# 3066H register map
File version: 1.0
Registers are 32-bit, access per field, reset 0x0 unless marked. A register's access mark holds for its fields unless they carry their own. Offsets are from the block's base; [hi:lo] are bit positions; {n}, {i} and the like mark numbered series; 'fields as' and 'values as' point back to an identical list.

## APT_XBAR — APT_XBAR peripheral interface
Base 0x14A1F000
0x00 TRIP_XBAR_IN31_0_CFG rw — TRIP_XBAR_IN31_0_CFG为TRIP XBAR INPUT配置寄存器。支持写保护。
  [31:0] rg_xbar_in31_0_inv — 选择TRIP X-BAR INPUT31~INPUT0是否取反，每个bit对应1个INPUT。 0：直通，不取反； 1：取反。
0x04 TRIP_XBAR_IN63_32_CFG rw — TRIP_XBAR_IN63_32_CFG为TRIP XBAR INPUT配置寄存器。支持写保护。
  [31:0] rg_xbar_in63_32_inv — 选择TRIP X-BAR INPUT63~INPUT32是否取反，每个bit对应1个INPUT。 0：直通，不取反； 1：取反。
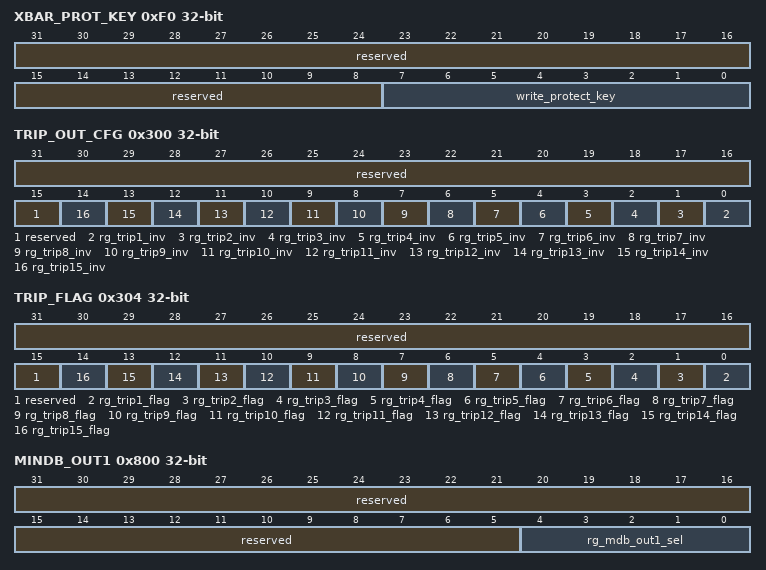
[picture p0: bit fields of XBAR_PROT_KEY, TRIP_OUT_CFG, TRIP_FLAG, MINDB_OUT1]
0xF0 XBAR_PROT_KEY — XBAR_PROT_KEY为XBAR保护配置寄存器。
  [31:8] reserved ro — 保留。
  [7:0] write_protect_key rw — XBAR写保护关键字。 0x55：软件可写支持写保护的寄存器； 其他：软件不可写支持写保护的寄存器，只可读。
{0xF0+0x10*i} TRIP{i}_IN31_0_CFG rw (i=1..15) — TRIP{i}_IN31_0_CFG为TRIP{i} INPUT31_0配置寄存器。支持写保护。
  [31:0] rg_xbar_in31_0_trip{i}_en — 选择TRIP X-BAR INPUT31~INPUT0是否对TRIP{i}使能，每个bit对应1个INPUT。 0：不使能； 1：使能。
{0xF4+0x10*i} TRIP{i}_IN63_32_CFG rw (i=1..15) — TRIP{i}_IN63_32_CFG为TRIP{i} INPUT63_32配置寄存器。支持写保护。
  [31:0] rg_xbar_in63_32_trip{i}_en — 选择TRIP X-BAR INPUT63~INPUT32是否对TRIP{i}使能，每个bit对应1个INPUT。 0：不使能； 1：使能。
0x300 TRIP_OUT_CFG — TRIP_OUT_CFG为TRIP输出配置寄存器。支持写保护。
  [31:15] reserved ro — 保留。
  [n-1] rg_trip{n}_inv rw (n=1..15) — 选择TRIP XBAR输出极性。 0：直通，不取反； 1：取反。
0x304 TRIP_FLAG access not given — TRIP_FLAG为TRIP标志寄存器。支持写保护。
  [31:15] reserved ro — 保留。
  [n-1] rg_trip{n}_flag (n=1..15) — TRIP{n}标志，TRIP{n}是否被触发。 0：TRIP{n}没被触发； 1：TRIP{n}被触发，软件写1清除。 信号上升沿触发置位，置位优先于软件清除。
0x800 MINDB_OUT1 — MINDB_OUT1为MINDB XBAR OUT1配置寄存器。支持写保护。
  [31:5] reserved ro — 保留。
  [4:0] rg_mdb_out1_sel rw — 选择MINDB XBAR OUT1输出来源。 0x0：APT0_DG_PWMA_NO_HR； 0x1：APT0_DG_PWMB_NO_HR； 0x2：APT1_DG_PWMA_NO_HR； 0x3：APT1_DG_PWMB_NO_HR； … 0x1E：APT15_DG_PWMA_NO_HR； 0x1F：APT15_DG_PWMA_NO_HR； 最大值到最后一个APT，其他值保留。
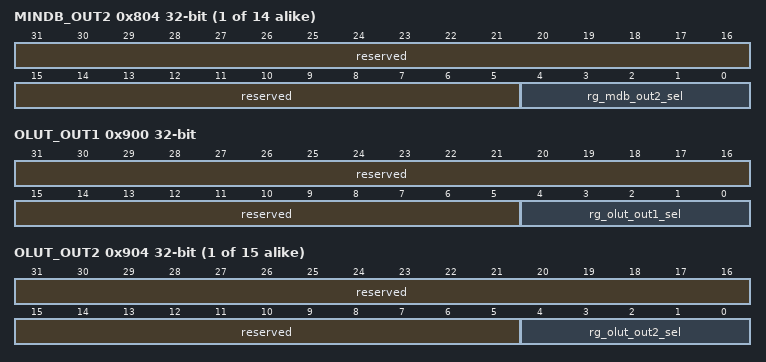
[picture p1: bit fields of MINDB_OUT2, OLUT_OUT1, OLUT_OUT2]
{0x7FC+4i} MINDB_OUT{i} (i=2..15) — MINDB_OUT{i}为MINDB XBAR OUT{i}配置寄存器。支持写保护。
  [31:5] reserved ro — 保留。
  [4:0] rg_mdb_out{i}_sel rw — 选择MINDB XBAR OUT{i}输出来源。
0x900 OLUT_OUT1 — OLUT_OUT1为OLUT XBAR OUT1配置寄存器。支持写保护。
  [31:5] reserved ro — 保留。
  [4:0] rg_olut_out1_sel rw — 选择OLUT XBAR OUT1输出来源。 0x0：APT0_MINDB_PWMA； 0x1：APT0_MINDB_PWMB； 0x2：APT1_MINDB_PWMA； 0x3：APT1_MINDB_PWMB； … 0x1E：APT15_MINDB_PWMA； 0x1F：APT15_MINDB_PWMB； 最大值到最后一个APT，其他值保留。
{0x8FC+4i} OLUT_OUT{i} (i=2..16) — OLUT_OUT{i}为OLUT XBAR OUT{i}配置寄存器。支持写保护。
  [31:5] reserved ro — 保留。
  [4:0] rg_olut_out{i}_sel rw — 选择OLUT XBAR OUT{i}输出来源。

## DLL — DLL peripheral interface
Base 0x14A1FF00
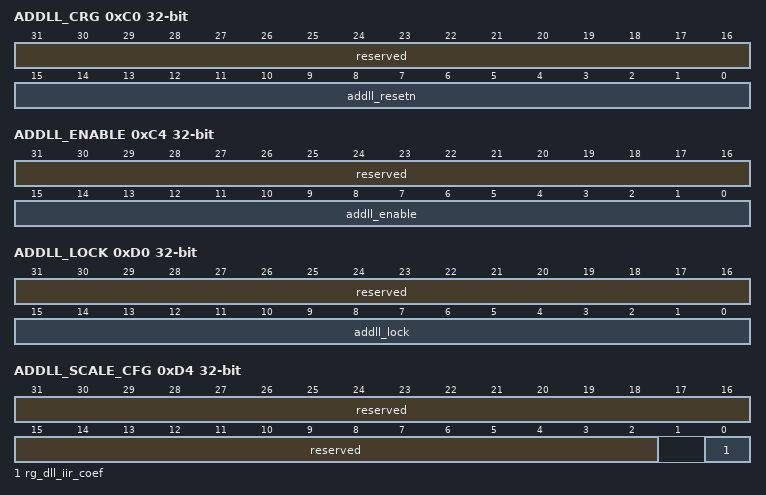
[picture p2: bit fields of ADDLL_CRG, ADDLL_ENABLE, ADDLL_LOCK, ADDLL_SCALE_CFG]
0xC0 ADDLL_CRG — ADDLL复位寄存器
  [31:16] reserved ro — 保留。
  [15:0] addll_resetn rw — ADDLL复位，bit[15]-bit[0]分别对应ADDLL15-ADDLL0复位。 0：复位； 1：不复位。
0xC4 ADDLL_ENABLE — ADDLL使能寄存器
  [31:16] reserved ro — 保留。
  [15:0] addll_enable rw — ADDLL使能，bit[15]-bit[0]分别对应ADDLL15-ADDLL0使能。 0：不使能； 1：使能。
0xC4 ADDLL_ENABLE — ADDLL使能寄存器
  fields as ADDLL_ENABLE
0xD0 ADDLL_LOCK ro — ADDLL锁定状态寄存器
  [31:16] reserved — 保留。
  [15:0] addll_lock — ADDLL锁定状态，bit[15]-bit[0]分别对应ADDLL15-ADDLL0锁定状态。 0：未锁定； 1：已锁定。
0xD4 ADDLL_SCALE_CFG — ADDLL SCLAE配置寄存器
  [31:2] reserved ro — 保留。
  [0] rg_dll_iir_coef rw — 对SCALE进行IIR滤波，滤波系数。 00：K=1/2； 01：K=1/4； 10：K=1/8。 其他：保留。

## CAPM_COMM — CAPM_COMM peripheral interface
Base 0x14B03000
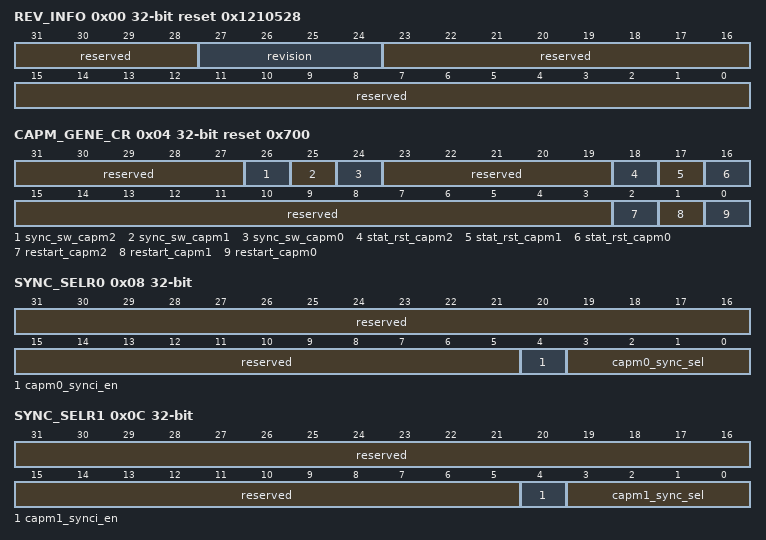
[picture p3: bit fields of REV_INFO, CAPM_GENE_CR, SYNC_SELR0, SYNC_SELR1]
0x00 REV_INFO ro reset 0x1210528 — REV_INFO为Revision Information，版本信息寄存器。
  [31:28] reserved — 保留。
  [27:24] revision — IP版本号。
  [23:0] reserved — 保留。
0x04 CAPM_GENE_CR reset 0x700 — CAPM_GENE_CR为Capture Module General Control Register，通用配置寄存器。
  [31:27] reserved ro — 保留。
  [26] sync_sw_capm2 rw write-1-clears — 触发CAPM2同步，TSR的值被同步为SYNC_PHS的值，同时重启捕获序列。软件写1后自动清零。 0：不同步； 1：同步。写1后自动清零。
  [25] sync_sw_capm1 rw write-1-clears — 触发CAPM1同步，TSR的值被同步为SYNC_PHS的值，同时重启捕获序列。软件写1后自动清零。 0：不同步； 1：同步。写1后自动清零。
  [24] sync_sw_capm0 rw write-1-clears — 触发CAPM0同步，TSR的值被同步为SYNC_PHS的值，同时重启捕获序列。软件写1后自动清零。 0：不同步； 1：同步。写1后自动清零。
  [23:19] reserved ro — 保留。
  [18] stat_rst_capm2 rw write-1-clears — CAPM2工作状态复位，复位范围包括：TSR计数器；EAR计数器；捕获序列；TSR分频计数器；原始中断。 0：不复位； 1：复位。写1后自动清零。
  [17] stat_rst_capm1 rw write-1-clears — CAPM1工作状态复位，复位范围包括：TSR计数器、EAR计数器、捕获序列、TSR分频计数器、原始中断。 0：不复位； 1：复位。写1后自动清零。
  [16] stat_rst_capm0 rw write-1-clears — CAPM0工作状态复位，复位范围包括：TSR计数器、EAR计数器、捕获序列、TSR分频计数器、原始中断。 0：不复位； 1：复位。写1后自动清零。
  [15:3] reserved ro — 保留。
  [2] restart_capm2 rw write-1-clears — CAPM2开始一次新的单轮次捕获。 0：不开始； 1：开始。写1后自动清零。
  [1] restart_capm1 rw write-1-clears — CAPM1开始一次新的单轮次捕获。 0：不开始； 1：开始。写1后自动清零。
  [0] restart_capm0 rw write-1-clears — CAPM0开始一次新的单轮次捕获。 0：不开始； 1：开始。写1后自动清零。
0x08 SYNC_SELR0 — SYNC_SELR0为Sync Selection Register(for CAPM0)，CAPM0同步设置选择寄存器。
  [31:5] reserved ro — 保留。
  [4] capm0_synci_en rw — CAPM0 硬件，软件同步使能。 0：不使能； 1：使能。
  [3:0] capm0_sync_sel rw — CAPM0的硬件同步源选择。 0x0：无同步源； 0x1：APT0同步输出信号APT0SYNCO； 0x2：APT1同步输出信号APT1SYNCO； 0x3：APT2同步输出信号APT2SYNCO； 0x4：APT3同步输出信号APT3SYNCO； 0x5：APT4同步输出信号APT4SYNCO； 0x6：APT5同步输出信号APT5SYNCO； 0x7：APT6同步输出信号APT6SYNCO； 0x8：APT7同步输出信号APT7SYNCO； 0x9：APT8同步输出信号APT8SYNCO； 其他：无同步源。
0x0C SYNC_SELR1 — SYNC_SELR1为Sync Selection Register(for CAPM1)，CAPM1同步设置选择寄存器。
  [31:5] reserved ro — 保留。
  [4] capm1_synci_en rw — CAPM1硬件，软件同步使能。 0：不使能； 1：使能。
  [3:0] capm1_sync_sel rw — CAPM1的硬件同步源选择： 同capm0_sync_sel。
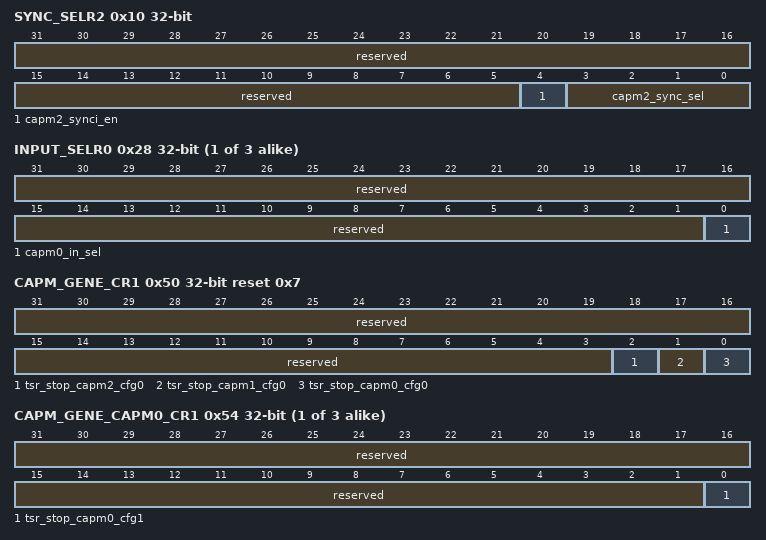
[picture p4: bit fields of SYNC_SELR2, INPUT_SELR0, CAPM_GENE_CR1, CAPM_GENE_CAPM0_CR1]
0x10 SYNC_SELR2 — SYNC_SELR2为Sync Selection Register(for CAPM2)，CAPM2同步设置选择寄存器。
  [31:5] reserved ro — 保留。
  [4] capm2_synci_en rw — CAPM2 硬件，软件同步使能。 0：不使能； 1：使能。
  [3:0] capm2_sync_sel rw — CAPM2的硬件同步源选择： 同capm0_sync_sel。
{0x28+4i} INPUT_SELR{i} (i=0..2) — INPUT_SELR{i}为Input Source Selection Register(for CAPM{i})，CAPM{i}输入源选择寄存器。
  [31:1] reserved ro — 保留。
  [0] capm{i}_in_sel rw — CAPM{i}输入源选择。 0：CAPM{i}_IN； 1：无。
0x50 CAPM_GENE_CR1 reset 0x7 — CAPM_GENE_CR1为CAPM general control Reg1，通用配置寄存器1，用来同时控制CAPM通道TSR启动/暂停。
  [31:3] reserved ro — 保留。
  [2] tsr_stop_capm2_cfg0 rw — CAPM2 TSR暂停计数使能。 0：CAPM2 TSR继续计数； 1：CAPM2 TSR暂停计数。 tsr_stop_capm2_cfg0和tsr_stop_capm2_cfg1任意一个生效都可以停止对应的计数。
  [1] tsr_stop_capm1_cfg0 rw — CAPM1 TSR暂停计数使能。 0：CAPM1 TSR继续计数； 1：CAPM1 TSR暂停计数。 tsr_stop_capm1_cfg0和tsr_stop_capm1_cfg1任意一个生效都可以停止对应的计数。
  [0] tsr_stop_capm0_cfg0 rw — CAPM0 TSR暂停计数使能。 0：CAPM0 TSR继续计数； 1：CAPM0 TSR暂停计数。 tsr_stop_capm0_cfg0和tsr_stop_capm0_cfg1任意一个生效都可以停止对应的计数。
{0x54+4i} CAPM_GENE_CAPM{i}_CR1 (i=0..2) — CAPM_GENE_CAPM{i}_CR1为CAPM{i} general control Reg1，CAPM{i}通用配置寄存器1，用来单独控制CAPM{i}通道TSR启动/暂停。
  [31:1] reserved ro — 保留。
  [0] tsr_stop_capm{i}_cfg1 rw — CAPM{i} TSR暂停计数使能。 0：CAPM{i} TSR继续计数； 1：CAPM{i} TSR暂停计数。 tsr_stop_capm{i}_cfg0和tsr_stop_capm{i}_cfg1任意一个生效都可以停止对应的计数。
